# MIMXRT1051 register map
Vendor: nxp.com; File version: 1.0
CPU: CM7 r0p1, little endian, MPU, FPU, VTOR, 4 interrupt priority bits
Registers are 32-bit, read-write, reset 0x0 unless marked. A register's access mark holds for its fields unless they carry their own. Offsets are from the block's base; [hi:lo] are bit positions.

## IOMUXC (part 2 of 4)
Base 0x401F8000; register names take the prefix IOMUXC_
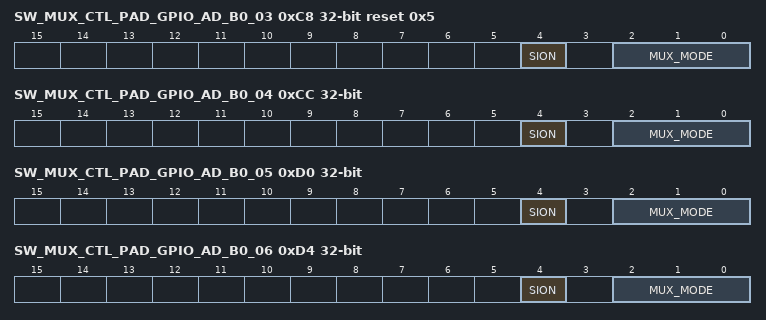
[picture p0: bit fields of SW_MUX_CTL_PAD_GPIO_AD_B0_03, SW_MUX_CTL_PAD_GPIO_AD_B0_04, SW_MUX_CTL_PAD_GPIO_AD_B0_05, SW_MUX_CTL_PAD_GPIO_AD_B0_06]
0xC8 SW_MUX_CTL_PAD_GPIO_AD_B0_03 reset 0x5 — SW_MUX_CTL_PAD_GPIO_AD_B0_03 SW MUX Control Register
  [4] SION — Software Input On Field.
    0=DISABLED (Input Path is determined by functionality); 1=ENABLED (Force input path of pad GPIO_AD_B0_03)
  [2:0] MUX_MODE — MUX Mode Select Field. Note: Some functions are available on multiple pins. A given function should not be selected for more than one pin.
    0=ALT0 (Select mux mode: ALT0 mux port: FLEXCAN2_RX of instance: flexcan2); 1=ALT1 (Select mux mode: ALT1 mux port: XBAR1_INOUT17 of instance: xbar1); 2=ALT2 (Select mux mode: ALT2 mux port: LPUART6_RXD of instance: lpuart6); 3=ALT3 (Select mux mode: ALT3 mux port: USB_OTG1_OC of instance: usb); 4=ALT4 (Select mux mode: ALT4 mux port: FLEXPWM1_PWM1_X of instance: flexpwm1); 5=ALT5 (Select mux mode: ALT5 mux port: GPIO1_IO03 of instance: gpio1); 6=ALT6 (Select mux mode: ALT6 mux port: REF_CLK_24M of instance: anatop); 7=ALT7 (Select mux mode: ALT7 mux port: LPSPI3_PCS0 of instance: lpspi3)
0xCC SW_MUX_CTL_PAD_GPIO_AD_B0_04 — SW_MUX_CTL_PAD_GPIO_AD_B0_04 SW MUX Control Register
  [4] SION — Software Input On Field.
    0=DISABLED (Input Path is determined by functionality); 1=ENABLED (Force input path of pad GPIO_AD_B0_04)
  [2:0] MUX_MODE — MUX Mode Select Field. Note: Some functions are available on multiple pins. A given function should not be selected for more than one pin.
    0=ALT0 (Select mux mode: ALT0 mux port: SRC_BOOT_MODE00 of instance: src); 1=ALT1 (Select mux mode: ALT1 mux port: MQS_RIGHT of instance: mqs); 2=ALT2 (Select mux mode: ALT2 mux port: ENET_TX_DATA03 of instance: enet); 3=ALT3 (Select mux mode: ALT3 mux port: SAI2_TX_SYNC of instance: sai2); 4=ALT4 (Select mux mode: ALT4 mux port: CSI_DATA09 of instance: csi); 5=ALT5 (Select mux mode: ALT5 mux port: GPIO1_IO04 of instance: gpio1); 6=ALT6 (Select mux mode: ALT6 mux port: PIT_TRIGGER00 of instance: pit); 7=ALT7 (Select mux mode: ALT7 mux port: LPSPI3_PCS1 of instance: lpspi3)
0xD0 SW_MUX_CTL_PAD_GPIO_AD_B0_05 — SW_MUX_CTL_PAD_GPIO_AD_B0_05 SW MUX Control Register
  [4] SION — Software Input On Field.
    0=DISABLED (Input Path is determined by functionality); 1=ENABLED (Force input path of pad GPIO_AD_B0_05)
  [2:0] MUX_MODE — MUX Mode Select Field. Note: Some functions are available on multiple pins. A given function should not be selected for more than one pin.
    0=ALT0 (Select mux mode: ALT0 mux port: SRC_BOOT_MODE01 of instance: src); 1=ALT1 (Select mux mode: ALT1 mux port: MQS_LEFT of instance: mqs); 2=ALT2 (Select mux mode: ALT2 mux port: ENET_TX_DATA02 of instance: enet); 3=ALT3 (Select mux mode: ALT3 mux port: SAI2_TX_BCLK of instance: sai2); 4=ALT4 (Select mux mode: ALT4 mux port: CSI_DATA08 of instance: csi); 5=ALT5 (Select mux mode: ALT5 mux port: GPIO1_IO05 of instance: gpio1); 6=ALT6 (Select mux mode: ALT6 mux port: XBAR1_INOUT17 of instance: xbar1); 7=ALT7 (Select mux mode: ALT7 mux port: LPSPI3_PCS2 of instance: lpspi3)
0xD4 SW_MUX_CTL_PAD_GPIO_AD_B0_06 — SW_MUX_CTL_PAD_GPIO_AD_B0_06 SW MUX Control Register
  [4] SION — Software Input On Field.
    0=DISABLED (Input Path is determined by functionality); 1=ENABLED (Force input path of pad GPIO_AD_B0_06)
  [2:0] MUX_MODE — MUX Mode Select Field. Note: Some functions are available on multiple pins. A given function should not be selected for more than one pin.
    0=ALT0 (Select mux mode: ALT0 mux port: JTAG_TMS of instance: jtag_mux); 1=ALT1 (Select mux mode: ALT1 mux port: GPT2_COMPARE1 of instance: gpt2); 2=ALT2 (Select mux mode: ALT2 mux port: ENET_RX_CLK of instance: enet); 3=ALT3 (Select mux mode: ALT3 mux port: SAI2_RX_BCLK of instance: sai2); 4=ALT4 (Select mux mode: ALT4 mux port: CSI_DATA07 of instance: csi); 5=ALT5 (Select mux mode: ALT5 mux port: GPIO1_IO06 of instance: gpio1); 6=ALT6 (Select mux mode: ALT6 mux port: XBAR1_INOUT18 of instance: xbar1); 7=ALT7 (Select mux mode: ALT7 mux port: LPSPI3_PCS3 of instance: lpspi3)
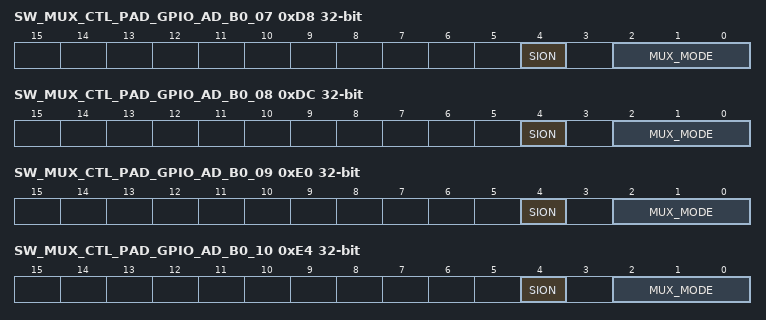
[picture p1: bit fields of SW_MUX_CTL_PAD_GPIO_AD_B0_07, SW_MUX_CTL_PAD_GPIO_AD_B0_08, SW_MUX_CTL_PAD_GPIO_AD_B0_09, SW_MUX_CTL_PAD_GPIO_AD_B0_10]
0xD8 SW_MUX_CTL_PAD_GPIO_AD_B0_07 — SW_MUX_CTL_PAD_GPIO_AD_B0_07 SW MUX Control Register
  [4] SION — Software Input On Field.
    0=DISABLED (Input Path is determined by functionality); 1=ENABLED (Force input path of pad GPIO_AD_B0_07)
  [2:0] MUX_MODE — MUX Mode Select Field. Note: Some functions are available on multiple pins. A given function should not be selected for more than one pin.
    0=ALT0 (Select mux mode: ALT0 mux port: JTAG_TCK of instance: jtag_mux); 1=ALT1 (Select mux mode: ALT1 mux port: GPT2_COMPARE2 of instance: gpt2); 2=ALT2 (Select mux mode: ALT2 mux port: ENET_TX_ER of instance: enet); 3=ALT3 (Select mux mode: ALT3 mux port: SAI2_RX_SYNC of instance: sai2); 4=ALT4 (Select mux mode: ALT4 mux port: CSI_DATA06 of instance: csi); 5=ALT5 (Select mux mode: ALT5 mux port: GPIO1_IO07 of instance: gpio1); 6=ALT6 (Select mux mode: ALT6 mux port: XBAR1_INOUT19 of instance: xbar1); 7=ALT7 (Select mux mode: ALT7 mux port: ENET_1588_EVENT3_OUT of instance: enet)
0xDC SW_MUX_CTL_PAD_GPIO_AD_B0_08 — SW_MUX_CTL_PAD_GPIO_AD_B0_08 SW MUX Control Register
  [4] SION — Software Input On Field.
    0=DISABLED (Input Path is determined by functionality); 1=ENABLED (Force input path of pad GPIO_AD_B0_08)
  [2:0] MUX_MODE — MUX Mode Select Field. Note: Some functions are available on multiple pins. A given function should not be selected for more than one pin.
    0=ALT0 (Select mux mode: ALT0 mux port: JTAG_MOD of instance: jtag_mux); 1=ALT1 (Select mux mode: ALT1 mux port: GPT2_COMPARE3 of instance: gpt2); 2=ALT2 (Select mux mode: ALT2 mux port: ENET_RX_DATA03 of instance: enet); 3=ALT3 (Select mux mode: ALT3 mux port: SAI2_RX_DATA of instance: sai2); 4=ALT4 (Select mux mode: ALT4 mux port: CSI_DATA05 of instance: csi); 5=ALT5 (Select mux mode: ALT5 mux port: GPIO1_IO08 of instance: gpio1); 6=ALT6 (Select mux mode: ALT6 mux port: XBAR1_IN20 of instance: xbar1); 7=ALT7 (Select mux mode: ALT7 mux port: ENET_1588_EVENT3_IN of instance: enet)
0xE0 SW_MUX_CTL_PAD_GPIO_AD_B0_09 — SW_MUX_CTL_PAD_GPIO_AD_B0_09 SW MUX Control Register
  [4] SION — Software Input On Field.
    0=DISABLED (Input Path is determined by functionality); 1=ENABLED (Force input path of pad GPIO_AD_B0_09)
  [2:0] MUX_MODE — MUX Mode Select Field. Note: Some functions are available on multiple pins. A given function should not be selected for more than one pin.
    0=ALT0 (Select mux mode: ALT0 mux port: JTAG_TDI of instance: jtag_mux); 1=ALT1 (Select mux mode: ALT1 mux port: FLEXPWM2_PWM3_A of instance: flexpwm2); 2=ALT2 (Select mux mode: ALT2 mux port: ENET_RX_DATA02 of instance: enet); 3=ALT3 (Select mux mode: ALT3 mux port: SAI2_TX_DATA of instance: sai2); 4=ALT4 (Select mux mode: ALT4 mux port: CSI_DATA04 of instance: csi); 5=ALT5 (Select mux mode: ALT5 mux port: GPIO1_IO09 of instance: gpio1); 6=ALT6 (Select mux mode: ALT6 mux port: XBAR1_IN21 of instance: xbar1); 7=ALT7 (Select mux mode: ALT7 mux port: GPT2_CLK of instance: gpt2)
0xE4 SW_MUX_CTL_PAD_GPIO_AD_B0_10 — SW_MUX_CTL_PAD_GPIO_AD_B0_10 SW MUX Control Register
  [4] SION — Software Input On Field.
    0=DISABLED (Input Path is determined by functionality); 1=ENABLED (Force input path of pad GPIO_AD_B0_10)
  [2:0] MUX_MODE — MUX Mode Select Field. Note: Some functions are available on multiple pins. A given function should not be selected for more than one pin.
    0=ALT0 (Select mux mode: ALT0 mux port: JTAG_TDO of instance: jtag_mux); 1=ALT1 (Select mux mode: ALT1 mux port: FLEXPWM1_PWM3_A of instance: flexpwm1); 2=ALT2 (Select mux mode: ALT2 mux port: ENET_CRS of instance: enet); 3=ALT3 (Select mux mode: ALT3 mux port: SAI2_MCLK of instance: sai2); 4=ALT4 (Select mux mode: ALT4 mux port: CSI_DATA03 of instance: csi); 5=ALT5 (Select mux mode: ALT5 mux port: GPIO1_IO10 of instance: gpio1); 6=ALT6 (Select mux mode: ALT6 mux port: XBAR1_IN22 of instance: xbar1); 7=ALT7 (Select mux mode: ALT7 mux port: ENET_1588_EVENT0_OUT of instance: enet)
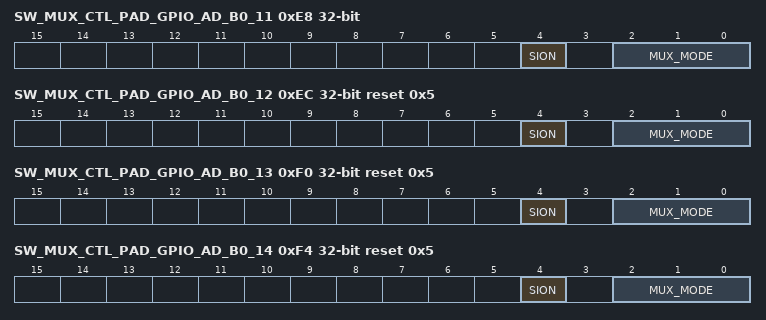
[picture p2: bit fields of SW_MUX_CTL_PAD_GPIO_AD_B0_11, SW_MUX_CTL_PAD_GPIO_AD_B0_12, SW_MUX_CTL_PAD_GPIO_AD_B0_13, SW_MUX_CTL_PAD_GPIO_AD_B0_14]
0xE8 SW_MUX_CTL_PAD_GPIO_AD_B0_11 — SW_MUX_CTL_PAD_GPIO_AD_B0_11 SW MUX Control Register
  [4] SION — Software Input On Field.
    0=DISABLED (Input Path is determined by functionality); 1=ENABLED (Force input path of pad GPIO_AD_B0_11)
  [2:0] MUX_MODE — MUX Mode Select Field. Note: Some functions are available on multiple pins. A given function should not be selected for more than one pin.
    0=ALT0 (Select mux mode: ALT0 mux port: JTAG_TRSTB of instance: jtag_mux); 1=ALT1 (Select mux mode: ALT1 mux port: FLEXPWM1_PWM3_B of instance: flexpwm1); 2=ALT2 (Select mux mode: ALT2 mux port: ENET_COL of instance: enet); 3=ALT3 (Select mux mode: ALT3 mux port: WDOG1_B of instance: wdog1); 4=ALT4 (Select mux mode: ALT4 mux port: CSI_DATA02 of instance: csi); 5=ALT5 (Select mux mode: ALT5 mux port: GPIO1_IO11 of instance: gpio1); 6=ALT6 (Select mux mode: ALT6 mux port: XBAR1_IN23 of instance: xbar1); 7=ALT7 (Select mux mode: ALT7 mux port: ENET_1588_EVENT0_IN of instance: enet)
0xEC SW_MUX_CTL_PAD_GPIO_AD_B0_12 reset 0x5 — SW_MUX_CTL_PAD_GPIO_AD_B0_12 SW MUX Control Register
  [4] SION — Software Input On Field.
    0=DISABLED (Input Path is determined by functionality); 1=ENABLED (Force input path of pad GPIO_AD_B0_12)
  [2:0] MUX_MODE — MUX Mode Select Field. Note: Some functions are available on multiple pins. A given function should not be selected for more than one pin.
    0=ALT0 (Select mux mode: ALT0 mux port: LPI2C4_SCL of instance: lpi2c4); 1=ALT1 (Select mux mode: ALT1 mux port: CCM_PMIC_READY of instance: ccm); 2=ALT2 (Select mux mode: ALT2 mux port: LPUART1_TXD of instance: lpuart1); 3=ALT3 (Select mux mode: ALT3 mux port: WDOG2_B of instance: wdog2); 4=ALT4 (Select mux mode: ALT4 mux port: FLEXPWM1_PWM2_X of instance: flexpwm1); 5=ALT5 (Select mux mode: ALT5 mux port: GPIO1_IO12 of instance: gpio1); 6=ALT6 (Select mux mode: ALT6 mux port: ENET_1588_EVENT1_OUT of instance: enet); 7=ALT7 (Select mux mode: ALT7 mux port: NMI of instance: CM7)
0xF0 SW_MUX_CTL_PAD_GPIO_AD_B0_13 reset 0x5 — SW_MUX_CTL_PAD_GPIO_AD_B0_13 SW MUX Control Register
  [4] SION — Software Input On Field.
    0=DISABLED (Input Path is determined by functionality); 1=ENABLED (Force input path of pad GPIO_AD_B0_13)
  [2:0] MUX_MODE — MUX Mode Select Field. Note: Some functions are available on multiple pins. A given function should not be selected for more than one pin.
    0=ALT0 (Select mux mode: ALT0 mux port: LPI2C4_SDA of instance: lpi2c4); 1=ALT1 (Select mux mode: ALT1 mux port: GPT1_CLK of instance: gpt1); 2=ALT2 (Select mux mode: ALT2 mux port: LPUART1_RXD of instance: lpuart1); 3=ALT3 (Select mux mode: ALT3 mux port: EWM_OUT_B of instance: ewm); 4=ALT4 (Select mux mode: ALT4 mux port: FLEXPWM1_PWM3_X of instance: flexpwm1); 5=ALT5 (Select mux mode: ALT5 mux port: GPIO1_IO13 of instance: gpio1); 6=ALT6 (Select mux mode: ALT6 mux port: ENET_1588_EVENT1_IN of instance: enet); 7=ALT7 (Select mux mode: ALT7 mux port: REF_CLK_24M of instance: anatop)
0xF4 SW_MUX_CTL_PAD_GPIO_AD_B0_14 reset 0x5 — SW_MUX_CTL_PAD_GPIO_AD_B0_14 SW MUX Control Register
  [4] SION — Software Input On Field.
    0=DISABLED (Input Path is determined by functionality); 1=ENABLED (Force input path of pad GPIO_AD_B0_14)
  [2:0] MUX_MODE — MUX Mode Select Field. Note: Some functions are available on multiple pins. A given function should not be selected for more than one pin.
    0=ALT0 (Select mux mode: ALT0 mux port: USB_OTG2_OC of instance: usb); 1=ALT1 (Select mux mode: ALT1 mux port: XBAR1_IN24 of instance: xbar1); 2=ALT2 (Select mux mode: ALT2 mux port: LPUART1_CTS_B of instance: lpuart1); 3=ALT3 (Select mux mode: ALT3 mux port: ENET_1588_EVENT0_OUT of instance: enet); 4=ALT4 (Select mux mode: ALT4 mux port: CSI_VSYNC of instance: csi); 5=ALT5 (Select mux mode: ALT5 mux port: GPIO1_IO14 of instance: gpio1); 6=ALT6 (Select mux mode: ALT6 mux port: FLEXCAN2_TX of instance: flexcan2)
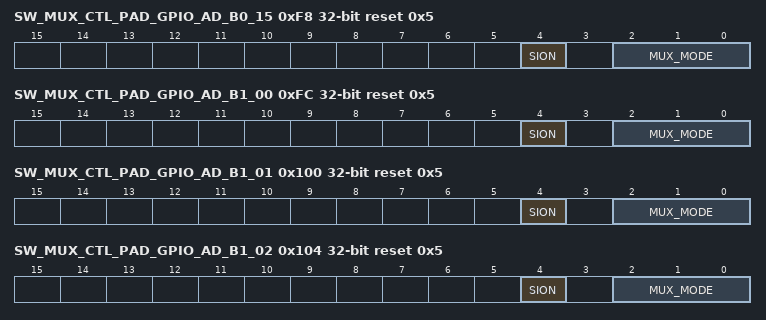
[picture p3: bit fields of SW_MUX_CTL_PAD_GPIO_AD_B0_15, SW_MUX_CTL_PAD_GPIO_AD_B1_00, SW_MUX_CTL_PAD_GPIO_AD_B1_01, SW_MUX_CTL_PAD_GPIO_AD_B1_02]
0xF8 SW_MUX_CTL_PAD_GPIO_AD_B0_15 reset 0x5 — SW_MUX_CTL_PAD_GPIO_AD_B0_15 SW MUX Control Register
  [4] SION — Software Input On Field.
    0=DISABLED (Input Path is determined by functionality); 1=ENABLED (Force input path of pad GPIO_AD_B0_15)
  [2:0] MUX_MODE — MUX Mode Select Field. Note: Some functions are available on multiple pins. A given function should not be selected for more than one pin.
    0=ALT0 (Select mux mode: ALT0 mux port: USB_OTG2_PWR of instance: usb); 1=ALT1 (Select mux mode: ALT1 mux port: XBAR1_IN25 of instance: xbar1); 2=ALT2 (Select mux mode: ALT2 mux port: LPUART1_RTS_B of instance: lpuart1); 3=ALT3 (Select mux mode: ALT3 mux port: ENET_1588_EVENT0_IN of instance: enet); 4=ALT4 (Select mux mode: ALT4 mux port: CSI_HSYNC of instance: csi); 5=ALT5 (Select mux mode: ALT5 mux port: GPIO1_IO15 of instance: gpio1); 6=ALT6 (Select mux mode: ALT6 mux port: FLEXCAN2_RX of instance: flexcan2); 7=ALT7 (Select mux mode: ALT7 mux port: WDOG1_WDOG_RST_B_DEB of instance: wdog1)
0xFC SW_MUX_CTL_PAD_GPIO_AD_B1_00 reset 0x5 — SW_MUX_CTL_PAD_GPIO_AD_B1_00 SW MUX Control Register
  [4] SION — Software Input On Field.
    0=DISABLED (Input Path is determined by functionality); 1=ENABLED (Force input path of pad GPIO_AD_B1_00)
  [2:0] MUX_MODE — MUX Mode Select Field. Note: Some functions are available on multiple pins. A given function should not be selected for more than one pin.
    0=ALT0 (Select mux mode: ALT0 mux port: USB_OTG2_ID of instance: anatop); 1=ALT1 (Select mux mode: ALT1 mux port: TMR3_TIMER0 of instance: qtimer3); 2=ALT2 (Select mux mode: ALT2 mux port: LPUART2_CTS_B of instance: lpuart2); 3=ALT3 (Select mux mode: ALT3 mux port: LPI2C1_SCL of instance: lpi2c1); 4=ALT4 (Select mux mode: ALT4 mux port: WDOG1_B of instance: wdog1); 5=ALT5 (Select mux mode: ALT5 mux port: GPIO1_IO16 of instance: gpio1); 6=ALT6 (Select mux mode: ALT6 mux port: USDHC1_WP of instance: usdhc1); 7=ALT7 (Select mux mode: ALT7 mux port: KPP_ROW07 of instance: kpp)
0x100 SW_MUX_CTL_PAD_GPIO_AD_B1_01 reset 0x5 — SW_MUX_CTL_PAD_GPIO_AD_B1_01 SW MUX Control Register
  [4] SION — Software Input On Field.
    0=DISABLED (Input Path is determined by functionality); 1=ENABLED (Force input path of pad GPIO_AD_B1_01)
  [2:0] MUX_MODE — MUX Mode Select Field. Note: Some functions are available on multiple pins. A given function should not be selected for more than one pin.
    0=ALT0 (Select mux mode: ALT0 mux port: USB_OTG1_PWR of instance: usb); 1=ALT1 (Select mux mode: ALT1 mux port: TMR3_TIMER1 of instance: qtimer3); 2=ALT2 (Select mux mode: ALT2 mux port: LPUART2_RTS_B of instance: lpuart2); 3=ALT3 (Select mux mode: ALT3 mux port: LPI2C1_SDA of instance: lpi2c1); 4=ALT4 (Select mux mode: ALT4 mux port: CCM_PMIC_READY of instance: ccm); 5=ALT5 (Select mux mode: ALT5 mux port: GPIO1_IO17 of instance: gpio1); 6=ALT6 (Select mux mode: ALT6 mux port: USDHC1_VSELECT of instance: usdhc1); 7=ALT7 (Select mux mode: ALT7 mux port: KPP_COL07 of instance: kpp)
0x104 SW_MUX_CTL_PAD_GPIO_AD_B1_02 reset 0x5 — SW_MUX_CTL_PAD_GPIO_AD_B1_02 SW MUX Control Register
  [4] SION — Software Input On Field.
    0=DISABLED (Input Path is determined by functionality); 1=ENABLED (Force input path of pad GPIO_AD_B1_02)
  [2:0] MUX_MODE — MUX Mode Select Field. Note: Some functions are available on multiple pins. A given function should not be selected for more than one pin.
    0=ALT0 (Select mux mode: ALT0 mux port: USB_OTG1_ID of instance: anatop); 1=ALT1 (Select mux mode: ALT1 mux port: TMR3_TIMER2 of instance: qtimer3); 2=ALT2 (Select mux mode: ALT2 mux port: LPUART2_TXD of instance: lpuart2); 3=ALT3 (Select mux mode: ALT3 mux port: SPDIF_OUT of instance: spdif); 4=ALT4 (Select mux mode: ALT4 mux port: ENET_1588_EVENT2_OUT of instance: enet); 5=ALT5 (Select mux mode: ALT5 mux port: GPIO1_IO18 of instance: gpio1); 6=ALT6 (Select mux mode: ALT6 mux port: USDHC1_CD_B of instance: usdhc1); 7=ALT7 (Select mux mode: ALT7 mux port: KPP_ROW06 of instance: kpp)
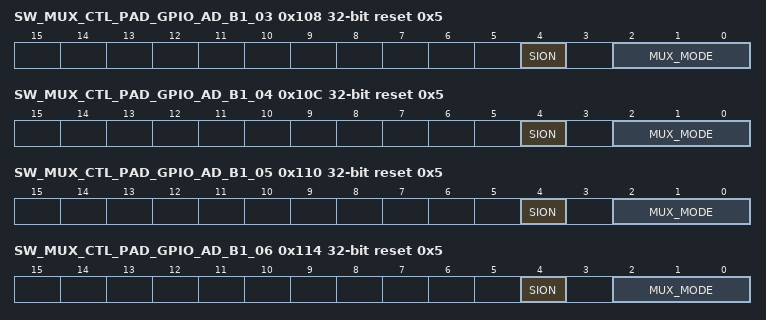
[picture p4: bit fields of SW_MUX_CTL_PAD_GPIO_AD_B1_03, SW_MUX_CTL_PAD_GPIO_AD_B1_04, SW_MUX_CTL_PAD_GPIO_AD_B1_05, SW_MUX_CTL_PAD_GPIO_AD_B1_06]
0x108 SW_MUX_CTL_PAD_GPIO_AD_B1_03 reset 0x5 — SW_MUX_CTL_PAD_GPIO_AD_B1_03 SW MUX Control Register
  [4] SION — Software Input On Field.
    0=DISABLED (Input Path is determined by functionality); 1=ENABLED (Force input path of pad GPIO_AD_B1_03)
  [2:0] MUX_MODE — MUX Mode Select Field. Note: Some functions are available on multiple pins. A given function should not be selected for more than one pin.
    0=ALT0 (Select mux mode: ALT0 mux port: USB_OTG1_OC of instance: usb); 1=ALT1 (Select mux mode: ALT1 mux port: TMR3_TIMER3 of instance: qtimer3); 2=ALT2 (Select mux mode: ALT2 mux port: LPUART2_RXD of instance: lpuart2); 3=ALT3 (Select mux mode: ALT3 mux port: SPDIF_IN of instance: spdif); 4=ALT4 (Select mux mode: ALT4 mux port: ENET_1588_EVENT2_IN of instance: enet); 5=ALT5 (Select mux mode: ALT5 mux port: GPIO1_IO19 of instance: gpio1); 6=ALT6 (Select mux mode: ALT6 mux port: USDHC2_CD_B of instance: usdhc2); 7=ALT7 (Select mux mode: ALT7 mux port: KPP_COL06 of instance: kpp)
0x10C SW_MUX_CTL_PAD_GPIO_AD_B1_04 reset 0x5 — SW_MUX_CTL_PAD_GPIO_AD_B1_04 SW MUX Control Register
  [4] SION — Software Input On Field.
    0=DISABLED (Input Path is determined by functionality); 1=ENABLED (Force input path of pad GPIO_AD_B1_04)
  [2:0] MUX_MODE — MUX Mode Select Field. Note: Some functions are available on multiple pins. A given function should not be selected for more than one pin.
    0=ALT0 (Select mux mode: ALT0 mux port: FLEXSPI_B_DATA3 of instance: flexspi); 1=ALT1 (Select mux mode: ALT1 mux port: ENET_MDC of instance: enet); 2=ALT2 (Select mux mode: ALT2 mux port: LPUART3_CTS_B of instance: lpuart3); 3=ALT3 (Select mux mode: ALT3 mux port: SPDIF_SR_CLK of instance: spdif); 4=ALT4 (Select mux mode: ALT4 mux port: CSI_PIXCLK of instance: csi); 5=ALT5 (Select mux mode: ALT5 mux port: GPIO1_IO20 of instance: gpio1); 6=ALT6 (Select mux mode: ALT6 mux port: USDHC2_DATA0 of instance: usdhc2); 7=ALT7 (Select mux mode: ALT7 mux port: KPP_ROW05 of instance: kpp)
0x110 SW_MUX_CTL_PAD_GPIO_AD_B1_05 reset 0x5 — SW_MUX_CTL_PAD_GPIO_AD_B1_05 SW MUX Control Register
  [4] SION — Software Input On Field.
    0=DISABLED (Input Path is determined by functionality); 1=ENABLED (Force input path of pad GPIO_AD_B1_05)
  [2:0] MUX_MODE — MUX Mode Select Field. Note: Some functions are available on multiple pins. A given function should not be selected for more than one pin.
    0=ALT0 (Select mux mode: ALT0 mux port: FLEXSPI_B_DATA2 of instance: flexspi); 1=ALT1 (Select mux mode: ALT1 mux port: ENET_MDIO of instance: enet); 2=ALT2 (Select mux mode: ALT2 mux port: LPUART3_RTS_B of instance: lpuart3); 3=ALT3 (Select mux mode: ALT3 mux port: SPDIF_OUT of instance: spdif); 4=ALT4 (Select mux mode: ALT4 mux port: CSI_MCLK of instance: csi); 5=ALT5 (Select mux mode: ALT5 mux port: GPIO1_IO21 of instance: gpio1); 6=ALT6 (Select mux mode: ALT6 mux port: USDHC2_DATA1 of instance: usdhc2); 7=ALT7 (Select mux mode: ALT7 mux port: KPP_COL05 of instance: kpp)
0x114 SW_MUX_CTL_PAD_GPIO_AD_B1_06 reset 0x5 — SW_MUX_CTL_PAD_GPIO_AD_B1_06 SW MUX Control Register
  [4] SION — Software Input On Field.
    0=DISABLED (Input Path is determined by functionality); 1=ENABLED (Force input path of pad GPIO_AD_B1_06)
  [2:0] MUX_MODE — MUX Mode Select Field. Note: Some functions are available on multiple pins. A given function should not be selected for more than one pin.
    0=ALT0 (Select mux mode: ALT0 mux port: FLEXSPI_B_DATA1 of instance: flexspi); 1=ALT1 (Select mux mode: ALT1 mux port: LPI2C3_SDA of instance: lpi2c3); 2=ALT2 (Select mux mode: ALT2 mux port: LPUART3_TXD of instance: lpuart3); 3=ALT3 (Select mux mode: ALT3 mux port: SPDIF_LOCK of instance: spdif); 4=ALT4 (Select mux mode: ALT4 mux port: CSI_VSYNC of instance: csi); 5=ALT5 (Select mux mode: ALT5 mux port: GPIO1_IO22 of instance: gpio1); 6=ALT6 (Select mux mode: ALT6 mux port: USDHC2_DATA2 of instance: usdhc2); 7=ALT7 (Select mux mode: ALT7 mux port: KPP_ROW04 of instance: kpp)
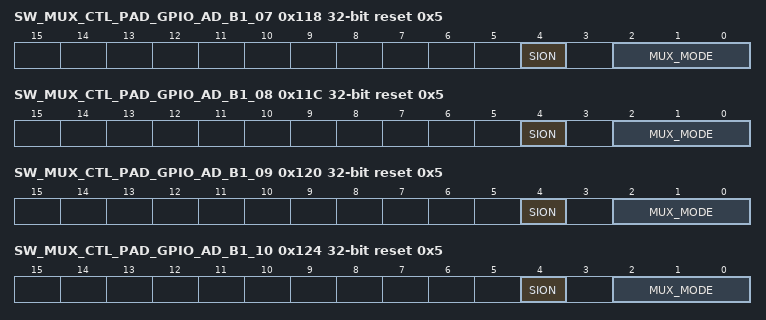
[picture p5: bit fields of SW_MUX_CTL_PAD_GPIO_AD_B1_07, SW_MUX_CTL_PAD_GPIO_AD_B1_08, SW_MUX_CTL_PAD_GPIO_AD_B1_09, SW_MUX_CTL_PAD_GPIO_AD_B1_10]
0x118 SW_MUX_CTL_PAD_GPIO_AD_B1_07 reset 0x5 — SW_MUX_CTL_PAD_GPIO_AD_B1_07 SW MUX Control Register
  [4] SION — Software Input On Field.
    0=DISABLED (Input Path is determined by functionality); 1=ENABLED (Force input path of pad GPIO_AD_B1_07)
  [2:0] MUX_MODE — MUX Mode Select Field. Note: Some functions are available on multiple pins. A given function should not be selected for more than one pin.
    0=ALT0 (Select mux mode: ALT0 mux port: FLEXSPI_B_DATA0 of instance: flexspi); 1=ALT1 (Select mux mode: ALT1 mux port: LPI2C3_SCL of instance: lpi2c3); 2=ALT2 (Select mux mode: ALT2 mux port: LPUART3_RXD of instance: lpuart3); 3=ALT3 (Select mux mode: ALT3 mux port: SPDIF_EXT_CLK of instance: spdif); 4=ALT4 (Select mux mode: ALT4 mux port: CSI_HSYNC of instance: csi); 5=ALT5 (Select mux mode: ALT5 mux port: GPIO1_IO23 of instance: gpio1); 6=ALT6 (Select mux mode: ALT6 mux port: USDHC2_DATA3 of instance: usdhc2); 7=ALT7 (Select mux mode: ALT7 mux port: KPP_COL04 of instance: kpp)
0x11C SW_MUX_CTL_PAD_GPIO_AD_B1_08 reset 0x5 — SW_MUX_CTL_PAD_GPIO_AD_B1_08 SW MUX Control Register
  [4] SION — Software Input On Field.
    0=DISABLED (Input Path is determined by functionality); 1=ENABLED (Force input path of pad GPIO_AD_B1_08)
  [2:0] MUX_MODE — MUX Mode Select Field. Note: Some functions are available on multiple pins. A given function should not be selected for more than one pin.
    0=ALT0 (Select mux mode: ALT0 mux port: FLEXSPI_A_SS1_B of instance: flexspi); 1=ALT1 (Select mux mode: ALT1 mux port: FLEXPWM4_PWM0_A of instance: flexpwm4); 2=ALT2 (Select mux mode: ALT2 mux port: FLEXCAN1_TX of instance: flexcan1); 3=ALT3 (Select mux mode: ALT3 mux port: CCM_PMIC_READY of instance: ccm); 4=ALT4 (Select mux mode: ALT4 mux port: CSI_DATA09 of instance: csi); 5=ALT5 (Select mux mode: ALT5 mux port: GPIO1_IO24 of instance: gpio1); 6=ALT6 (Select mux mode: ALT6 mux port: USDHC2_CMD of instance: usdhc2); 7=ALT7 (Select mux mode: ALT7 mux port: KPP_ROW03 of instance: kpp)
0x120 SW_MUX_CTL_PAD_GPIO_AD_B1_09 reset 0x5 — SW_MUX_CTL_PAD_GPIO_AD_B1_09 SW MUX Control Register
  [4] SION — Software Input On Field.
    0=DISABLED (Input Path is determined by functionality); 1=ENABLED (Force input path of pad GPIO_AD_B1_09)
  [2:0] MUX_MODE — MUX Mode Select Field. Note: Some functions are available on multiple pins. A given function should not be selected for more than one pin.
    0=ALT0 (Select mux mode: ALT0 mux port: FLEXSPI_A_DQS of instance: flexspi); 1=ALT1 (Select mux mode: ALT1 mux port: FLEXPWM4_PWM1_A of instance: flexpwm4); 2=ALT2 (Select mux mode: ALT2 mux port: FLEXCAN1_RX of instance: flexcan1); 3=ALT3 (Select mux mode: ALT3 mux port: SAI1_MCLK of instance: sai1); 4=ALT4 (Select mux mode: ALT4 mux port: CSI_DATA08 of instance: csi); 5=ALT5 (Select mux mode: ALT5 mux port: GPIO1_IO25 of instance: gpio1); 6=ALT6 (Select mux mode: ALT6 mux port: USDHC2_CLK of instance: usdhc2); 7=ALT7 (Select mux mode: ALT7 mux port: KPP_COL03 of instance: kpp)
0x124 SW_MUX_CTL_PAD_GPIO_AD_B1_10 reset 0x5 — SW_MUX_CTL_PAD_GPIO_AD_B1_10 SW MUX Control Register
  [4] SION — Software Input On Field.
    0=DISABLED (Input Path is determined by functionality); 1=ENABLED (Force input path of pad GPIO_AD_B1_10)
  [2:0] MUX_MODE — MUX Mode Select Field. Note: Some functions are available on multiple pins. A given function should not be selected for more than one pin.
    0=ALT0 (Select mux mode: ALT0 mux port: FLEXSPI_A_DATA3 of instance: flexspi); 1=ALT1 (Select mux mode: ALT1 mux port: WDOG1_B of instance: wdog1); 2=ALT2 (Select mux mode: ALT2 mux port: LPUART8_TXD of instance: lpuart8); 3=ALT3 (Select mux mode: ALT3 mux port: SAI1_RX_SYNC of instance: sai1); 4=ALT4 (Select mux mode: ALT4 mux port: CSI_DATA07 of instance: csi); 5=ALT5 (Select mux mode: ALT5 mux port: GPIO1_IO26 of instance: gpio1); 6=ALT6 (Select mux mode: ALT6 mux port: USDHC2_WP of instance: usdhc2); 7=ALT7 (Select mux mode: ALT7 mux port: KPP_ROW02 of instance: kpp)
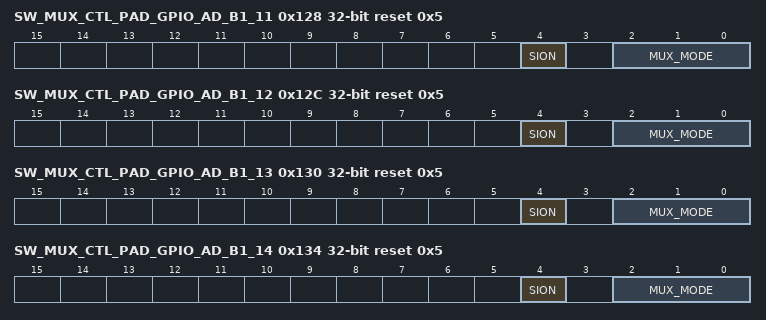
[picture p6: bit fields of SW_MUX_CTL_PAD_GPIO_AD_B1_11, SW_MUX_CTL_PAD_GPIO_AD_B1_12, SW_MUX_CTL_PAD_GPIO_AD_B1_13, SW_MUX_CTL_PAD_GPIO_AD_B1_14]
0x128 SW_MUX_CTL_PAD_GPIO_AD_B1_11 reset 0x5 — SW_MUX_CTL_PAD_GPIO_AD_B1_11 SW MUX Control Register
  [4] SION — Software Input On Field.
    0=DISABLED (Input Path is determined by functionality); 1=ENABLED (Force input path of pad GPIO_AD_B1_11)
  [2:0] MUX_MODE — MUX Mode Select Field. Note: Some functions are available on multiple pins. A given function should not be selected for more than one pin.
    0=ALT0 (Select mux mode: ALT0 mux port: FLEXSPI_A_DATA2 of instance: flexspi); 1=ALT1 (Select mux mode: ALT1 mux port: EWM_OUT_B of instance: ewm); 2=ALT2 (Select mux mode: ALT2 mux port: LPUART8_RXD of instance: lpuart8); 3=ALT3 (Select mux mode: ALT3 mux port: SAI1_RX_BCLK of instance: sai1); 4=ALT4 (Select mux mode: ALT4 mux port: CSI_DATA06 of instance: csi); 5=ALT5 (Select mux mode: ALT5 mux port: GPIO1_IO27 of instance: gpio1); 6=ALT6 (Select mux mode: ALT6 mux port: USDHC2_RESET_B of instance: usdhc2); 7=ALT7 (Select mux mode: ALT7 mux port: KPP_COL02 of instance: kpp)
0x12C SW_MUX_CTL_PAD_GPIO_AD_B1_12 reset 0x5 — SW_MUX_CTL_PAD_GPIO_AD_B1_12 SW MUX Control Register
  [4] SION — Software Input On Field.
    0=DISABLED (Input Path is determined by functionality); 1=ENABLED (Force input path of pad GPIO_AD_B1_12)
  [2:0] MUX_MODE — MUX Mode Select Field. Note: Some functions are available on multiple pins. A given function should not be selected for more than one pin.
    0=ALT0 (Select mux mode: ALT0 mux port: FLEXSPI_A_DATA1 of instance: flexspi); 1=ALT1 (Select mux mode: ALT1 mux port: ACMP1_OUT of instance: acmp); 2=ALT2 (Select mux mode: ALT2 mux port: LPSPI3_PCS0 of instance: lpspi3); 3=ALT3 (Select mux mode: ALT3 mux port: SAI1_RX_DATA00 of instance: sai1); 4=ALT4 (Select mux mode: ALT4 mux port: CSI_DATA05 of instance: csi); 5=ALT5 (Select mux mode: ALT5 mux port: GPIO1_IO28 of instance: gpio1); 6=ALT6 (Select mux mode: ALT6 mux port: USDHC2_DATA4 of instance: usdhc2); 7=ALT7 (Select mux mode: ALT7 mux port: KPP_ROW01 of instance: kpp)
0x130 SW_MUX_CTL_PAD_GPIO_AD_B1_13 reset 0x5 — SW_MUX_CTL_PAD_GPIO_AD_B1_13 SW MUX Control Register
  [4] SION — Software Input On Field.
    0=DISABLED (Input Path is determined by functionality); 1=ENABLED (Force input path of pad GPIO_AD_B1_13)
  [2:0] MUX_MODE — MUX Mode Select Field. Note: Some functions are available on multiple pins. A given function should not be selected for more than one pin.
    0=ALT0 (Select mux mode: ALT0 mux port: FLEXSPI_A_DATA00 of instance: flexspi); 1=ALT1 (Select mux mode: ALT1 mux port: ACMP2_OUT of instance: acmp); 2=ALT2 (Select mux mode: ALT2 mux port: LPSPI3_SDI of instance: lpspi3); 3=ALT3 (Select mux mode: ALT3 mux port: SAI1_TX_DATA00 of instance: sai1); 4=ALT4 (Select mux mode: ALT4 mux port: CSI_DATA04 of instance: csi); 5=ALT5 (Select mux mode: ALT5 mux port: GPIO1_IO29 of instance: gpio1); 6=ALT6 (Select mux mode: ALT6 mux port: USDHC2_DATA5 of instance: usdhc2); 7=ALT7 (Select mux mode: ALT7 mux port: KPP_COL01 of instance: kpp)
0x134 SW_MUX_CTL_PAD_GPIO_AD_B1_14 reset 0x5 — SW_MUX_CTL_PAD_GPIO_AD_B1_14 SW MUX Control Register
  [4] SION — Software Input On Field.
    0=DISABLED (Input Path is determined by functionality); 1=ENABLED (Force input path of pad GPIO_AD_B1_14)
  [2:0] MUX_MODE — MUX Mode Select Field. Note: Some functions are available on multiple pins. A given function should not be selected for more than one pin.
    0=ALT0 (Select mux mode: ALT0 mux port: FLEXSPI_A_SCLK of instance: flexspi); 1=ALT1 (Select mux mode: ALT1 mux port: ACMP3_OUT of instance: acmp); 2=ALT2 (Select mux mode: ALT2 mux port: LPSPI3_SDO of instance: lpspi3); 3=ALT3 (Select mux mode: ALT3 mux port: SAI1_TX_BCLK of instance: sai1); 4=ALT4 (Select mux mode: ALT4 mux port: CSI_DATA03 of instance: csi); 5=ALT5 (Select mux mode: ALT5 mux port: GPIO1_IO30 of instance: gpio1); 6=ALT6 (Select mux mode: ALT6 mux port: USDHC2_DATA6 of instance: usdhc2); 7=ALT7 (Select mux mode: ALT7 mux port: KPP_ROW00 of instance: kpp)
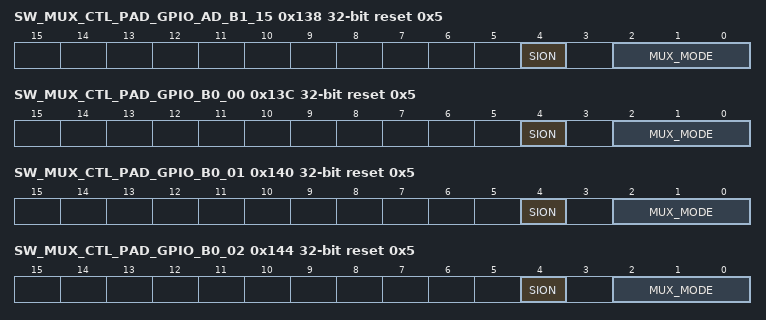
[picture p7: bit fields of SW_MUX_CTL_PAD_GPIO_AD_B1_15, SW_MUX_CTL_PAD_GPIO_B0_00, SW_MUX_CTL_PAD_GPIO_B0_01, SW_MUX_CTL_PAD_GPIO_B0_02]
0x138 SW_MUX_CTL_PAD_GPIO_AD_B1_15 reset 0x5 — SW_MUX_CTL_PAD_GPIO_AD_B1_15 SW MUX Control Register
  [4] SION — Software Input On Field.
    0=DISABLED (Input Path is determined by functionality); 1=ENABLED (Force input path of pad GPIO_AD_B1_15)
  [2:0] MUX_MODE — MUX Mode Select Field. Note: Some functions are available on multiple pins. A given function should not be selected for more than one pin.
    0=ALT0 (Select mux mode: ALT0 mux port: FLEXSPI_A_SS0_B of instance: flexspi); 1=ALT1 (Select mux mode: ALT1 mux port: ACMP4_OUT of instance: acmp); 2=ALT2 (Select mux mode: ALT2 mux port: LPSPI3_SCK of instance: lpspi3); 3=ALT3 (Select mux mode: ALT3 mux port: SAI1_TX_SYNC of instance: sai1); 4=ALT4 (Select mux mode: ALT4 mux port: CSI_DATA02 of instance: csi); 5=ALT5 (Select mux mode: ALT5 mux port: GPIO1_IO31 of instance: gpio1); 6=ALT6 (Select mux mode: ALT6 mux port: USDHC2_DATA7 of instance: usdhc2); 7=ALT7 (Select mux mode: ALT7 mux port: KPP_COL00 of instance: kpp)
0x13C SW_MUX_CTL_PAD_GPIO_B0_00 reset 0x5 — SW_MUX_CTL_PAD_GPIO_B0_00 SW MUX Control Register
  [4] SION — Software Input On Field.
    0=DISABLED (Input Path is determined by functionality); 1=ENABLED (Force input path of pad GPIO_B0_00)
  [2:0] MUX_MODE — MUX Mode Select Field. Note: Some functions are available on multiple pins. A given function should not be selected for more than one pin.
    0=ALT0 (Select mux mode: ALT0 mux port: LCD_CLK of instance: lcdif); 1=ALT1 (Select mux mode: ALT1 mux port: TMR1_TIMER0 of instance: qtimer1); 2=ALT2 (Select mux mode: ALT2 mux port: MQS_RIGHT of instance: mqs); 3=ALT3 (Select mux mode: ALT3 mux port: LPSPI4_PCS0 of instance: lpspi4); 4=ALT4 (Select mux mode: ALT4 mux port: FLEXIO2_D00 of instance: flexio2); 5=ALT5 (Select mux mode: ALT5 mux port: GPIO2_IO00 of instance: gpio2); 6=ALT6 (Select mux mode: ALT6 mux port: SEMC_CSX1 of instance: semc)
0x140 SW_MUX_CTL_PAD_GPIO_B0_01 reset 0x5 — SW_MUX_CTL_PAD_GPIO_B0_01 SW MUX Control Register
  [4] SION — Software Input On Field.
    0=DISABLED (Input Path is determined by functionality); 1=ENABLED (Force input path of pad GPIO_B0_01)
  [2:0] MUX_MODE — MUX Mode Select Field. Note: Some functions are available on multiple pins. A given function should not be selected for more than one pin.
    0=ALT0 (Select mux mode: ALT0 mux port: LCD_ENABLE of instance: lcdif); 1=ALT1 (Select mux mode: ALT1 mux port: TMR1_TIMER1 of instance: qtimer1); 2=ALT2 (Select mux mode: ALT2 mux port: MQS_LEFT of instance: mqs); 3=ALT3 (Select mux mode: ALT3 mux port: LPSPI4_SDI of instance: lpspi4); 4=ALT4 (Select mux mode: ALT4 mux port: FLEXIO2_D01 of instance: flexio2); 5=ALT5 (Select mux mode: ALT5 mux port: GPIO2_IO01 of instance: gpio2); 6=ALT6 (Select mux mode: ALT6 mux port: SEMC_CSX2 of instance: semc)
0x144 SW_MUX_CTL_PAD_GPIO_B0_02 reset 0x5 — SW_MUX_CTL_PAD_GPIO_B0_02 SW MUX Control Register
  [4] SION — Software Input On Field.
    0=DISABLED (Input Path is determined by functionality); 1=ENABLED (Force input path of pad GPIO_B0_02)
  [2:0] MUX_MODE — MUX Mode Select Field. Note: Some functions are available on multiple pins. A given function should not be selected for more than one pin.
    0=ALT0 (Select mux mode: ALT0 mux port: LCD_HSYNC of instance: lcdif); 1=ALT1 (Select mux mode: ALT1 mux port: TMR1_TIMER2 of instance: qtimer1); 2=ALT2 (Select mux mode: ALT2 mux port: FLEXCAN1_TX of instance: flexcan1); 3=ALT3 (Select mux mode: ALT3 mux port: LPSPI4_SDO of instance: lpspi4); 4=ALT4 (Select mux mode: ALT4 mux port: FLEXIO2_D02 of instance: flexio2); 5=ALT5 (Select mux mode: ALT5 mux port: GPIO2_IO02 of instance: gpio2); 6=ALT6 (Select mux mode: ALT6 mux port: SEMC_CSX3 of instance: semc)
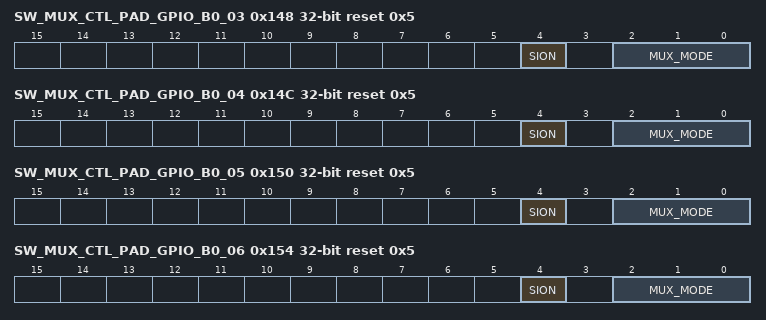
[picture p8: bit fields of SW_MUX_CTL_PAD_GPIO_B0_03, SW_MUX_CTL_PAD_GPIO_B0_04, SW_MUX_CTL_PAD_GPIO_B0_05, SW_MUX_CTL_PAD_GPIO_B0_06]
0x148 SW_MUX_CTL_PAD_GPIO_B0_03 reset 0x5 — SW_MUX_CTL_PAD_GPIO_B0_03 SW MUX Control Register
  [4] SION — Software Input On Field.
    0=DISABLED (Input Path is determined by functionality); 1=ENABLED (Force input path of pad GPIO_B0_03)
  [2:0] MUX_MODE — MUX Mode Select Field. Note: Some functions are available on multiple pins. A given function should not be selected for more than one pin.
    0=ALT0 (Select mux mode: ALT0 mux port: LCD_VSYNC of instance: lcdif); 1=ALT1 (Select mux mode: ALT1 mux port: TMR2_TIMER0 of instance: qtimer2); 2=ALT2 (Select mux mode: ALT2 mux port: FLEXCAN1_RX of instance: flexcan1); 3=ALT3 (Select mux mode: ALT3 mux port: LPSPI4_SCK of instance: lpspi4); 4=ALT4 (Select mux mode: ALT4 mux port: FLEXIO2_D03 of instance: flexio2); 5=ALT5 (Select mux mode: ALT5 mux port: GPIO2_IO03 of instance: gpio2); 6=ALT6 (Select mux mode: ALT6 mux port: WDOG2_RESET_B_DEB of instance: wdog2)
0x14C SW_MUX_CTL_PAD_GPIO_B0_04 reset 0x5 — SW_MUX_CTL_PAD_GPIO_B0_04 SW MUX Control Register
  [4] SION — Software Input On Field.
    0=DISABLED (Input Path is determined by functionality); 1=ENABLED (Force input path of pad GPIO_B0_04)
  [2:0] MUX_MODE — MUX Mode Select Field. Note: Some functions are available on multiple pins. A given function should not be selected for more than one pin.
    0=ALT0 (Select mux mode: ALT0 mux port: LCD_DATA00 of instance: lcdif); 1=ALT1 (Select mux mode: ALT1 mux port: TMR2_TIMER1 of instance: qtimer2); 2=ALT2 (Select mux mode: ALT2 mux port: LPI2C2_SCL of instance: lpi2c2); 3=ALT3 (Select mux mode: ALT3 mux port: ARM_TRACE00 of instance: cm7_mx6rt); 4=ALT4 (Select mux mode: ALT4 mux port: FLEXIO2_D04 of instance: flexio2); 5=ALT5 (Select mux mode: ALT5 mux port: GPIO2_IO04 of instance: gpio2); 6=ALT6 (Select mux mode: ALT6 mux port: SRC_BT_CFG00 of instance: src)
0x150 SW_MUX_CTL_PAD_GPIO_B0_05 reset 0x5 — SW_MUX_CTL_PAD_GPIO_B0_05 SW MUX Control Register
  [4] SION — Software Input On Field.
    0=DISABLED (Input Path is determined by functionality); 1=ENABLED (Force input path of pad GPIO_B0_05)
  [2:0] MUX_MODE — MUX Mode Select Field. Note: Some functions are available on multiple pins. A given function should not be selected for more than one pin.
    0=ALT0 (Select mux mode: ALT0 mux port: LCD_DATA01 of instance: lcdif); 1=ALT1 (Select mux mode: ALT1 mux port: TMR2_TIMER2 of instance: qtimer2); 2=ALT2 (Select mux mode: ALT2 mux port: LPI2C2_SDA of instance: lpi2c2); 3=ALT3 (Select mux mode: ALT3 mux port: ARM_TRACE01 of instance: cm7_mx6rt); 4=ALT4 (Select mux mode: ALT4 mux port: FLEXIO2_D05 of instance: flexio2); 5=ALT5 (Select mux mode: ALT5 mux port: GPIO2_IO05 of instance: gpio2); 6=ALT6 (Select mux mode: ALT6 mux port: SRC_BT_CFG01 of instance: src)
0x154 SW_MUX_CTL_PAD_GPIO_B0_06 reset 0x5 — SW_MUX_CTL_PAD_GPIO_B0_06 SW MUX Control Register
  [4] SION — Software Input On Field.
    0=DISABLED (Input Path is determined by functionality); 1=ENABLED (Force input path of pad GPIO_B0_06)
  [2:0] MUX_MODE — MUX Mode Select Field. Note: Some functions are available on multiple pins. A given function should not be selected for more than one pin.
    0=ALT0 (Select mux mode: ALT0 mux port: LCD_DATA02 of instance: lcdif); 1=ALT1 (Select mux mode: ALT1 mux port: TMR3_TIMER0 of instance: qtimer3); 2=ALT2 (Select mux mode: ALT2 mux port: FLEXPWM2_PWM0_A of instance: flexpwm2); 3=ALT3 (Select mux mode: ALT3 mux port: ARM_TRACE02 of instance: cm7_mx6rt); 4=ALT4 (Select mux mode: ALT4 mux port: FLEXIO2_D06 of instance: flexio2); 5=ALT5 (Select mux mode: ALT5 mux port: GPIO2_IO06 of instance: gpio2); 6=ALT6 (Select mux mode: ALT6 mux port: SRC_BT_CFG02 of instance: src)
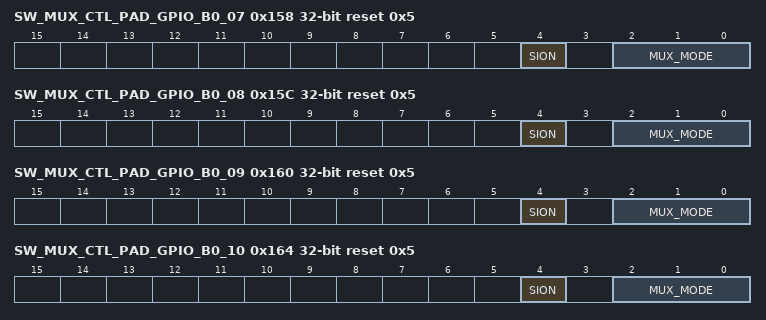
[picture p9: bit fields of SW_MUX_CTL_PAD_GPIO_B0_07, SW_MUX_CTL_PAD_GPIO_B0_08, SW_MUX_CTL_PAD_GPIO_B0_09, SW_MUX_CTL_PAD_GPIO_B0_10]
0x158 SW_MUX_CTL_PAD_GPIO_B0_07 reset 0x5 — SW_MUX_CTL_PAD_GPIO_B0_07 SW MUX Control Register
  [4] SION — Software Input On Field.
    0=DISABLED (Input Path is determined by functionality); 1=ENABLED (Force input path of pad GPIO_B0_07)
  [2:0] MUX_MODE — MUX Mode Select Field. Note: Some functions are available on multiple pins. A given function should not be selected for more than one pin.
    0=ALT0 (Select mux mode: ALT0 mux port: LCD_DATA03 of instance: lcdif); 1=ALT1 (Select mux mode: ALT1 mux port: TMR3_TIMER1 of instance: qtimer3); 2=ALT2 (Select mux mode: ALT2 mux port: FLEXPWM2_PWM0_B of instance: flexpwm2); 3=ALT3 (Select mux mode: ALT3 mux port: ARM_TRACE03 of instance: cm7_mx6rt); 4=ALT4 (Select mux mode: ALT4 mux port: FLEXIO2_D07 of instance: flexio2); 5=ALT5 (Select mux mode: ALT5 mux port: GPIO2_IO07 of instance: gpio2); 6=ALT6 (Select mux mode: ALT6 mux port: SRC_BT_CFG03 of instance: src)
0x15C SW_MUX_CTL_PAD_GPIO_B0_08 reset 0x5 — SW_MUX_CTL_PAD_GPIO_B0_08 SW MUX Control Register
  [4] SION — Software Input On Field.
    0=DISABLED (Input Path is determined by functionality); 1=ENABLED (Force input path of pad GPIO_B0_08)
  [2:0] MUX_MODE — MUX Mode Select Field. Note: Some functions are available on multiple pins. A given function should not be selected for more than one pin.
    0=ALT0 (Select mux mode: ALT0 mux port: LCD_DATA04 of instance: lcdif); 1=ALT1 (Select mux mode: ALT1 mux port: TMR3_TIMER2 of instance: qtimer3); 2=ALT2 (Select mux mode: ALT2 mux port: FLEXPWM2_PWM1_A of instance: flexpwm2); 3=ALT3 (Select mux mode: ALT3 mux port: LPUART3_TXD of instance: lpuart3); 4=ALT4 (Select mux mode: ALT4 mux port: FLEXIO2_D08 of instance: flexio2); 5=ALT5 (Select mux mode: ALT5 mux port: GPIO2_IO08 of instance: gpio2); 6=ALT6 (Select mux mode: ALT6 mux port: SRC_BT_CFG04 of instance: src)
0x160 SW_MUX_CTL_PAD_GPIO_B0_09 reset 0x5 — SW_MUX_CTL_PAD_GPIO_B0_09 SW MUX Control Register
  [4] SION — Software Input On Field.
    0=DISABLED (Input Path is determined by functionality); 1=ENABLED (Force input path of pad GPIO_B0_09)
  [2:0] MUX_MODE — MUX Mode Select Field. Note: Some functions are available on multiple pins. A given function should not be selected for more than one pin.
    0=ALT0 (Select mux mode: ALT0 mux port: LCD_DATA05 of instance: lcdif); 1=ALT1 (Select mux mode: ALT1 mux port: TMR4_TIMER0 of instance: qtimer4); 2=ALT2 (Select mux mode: ALT2 mux port: FLEXPWM2_PWM1_B of instance: flexpwm2); 3=ALT3 (Select mux mode: ALT3 mux port: LPUART3_RXD of instance: lpuart3); 4=ALT4 (Select mux mode: ALT4 mux port: FLEXIO2_D09 of instance: flexio2); 5=ALT5 (Select mux mode: ALT5 mux port: GPIO2_IO09 of instance: gpio2); 6=ALT6 (Select mux mode: ALT6 mux port: SRC_BT_CFG05 of instance: src)
0x164 SW_MUX_CTL_PAD_GPIO_B0_10 reset 0x5 — SW_MUX_CTL_PAD_GPIO_B0_10 SW MUX Control Register
  [4] SION — Software Input On Field.
    0=DISABLED (Input Path is determined by functionality); 1=ENABLED (Force input path of pad GPIO_B0_10)
  [2:0] MUX_MODE — MUX Mode Select Field. Note: Some functions are available on multiple pins. A given function should not be selected for more than one pin.
    0=ALT0 (Select mux mode: ALT0 mux port: LCD_DATA06 of instance: lcdif); 1=ALT1 (Select mux mode: ALT1 mux port: TMR4_TIMER1 of instance: qtimer4); 2=ALT2 (Select mux mode: ALT2 mux port: FLEXPWM2_PWM2_A of instance: flexpwm2); 3=ALT3 (Select mux mode: ALT3 mux port: SAI1_TX_DATA03 of instance: sai1); 4=ALT4 (Select mux mode: ALT4 mux port: FLEXIO2_D10 of instance: flexio2); 5=ALT5 (Select mux mode: ALT5 mux port: GPIO2_IO10 of instance: gpio2); 6=ALT6 (Select mux mode: ALT6 mux port: SRC_BT_CFG06 of instance: src)
